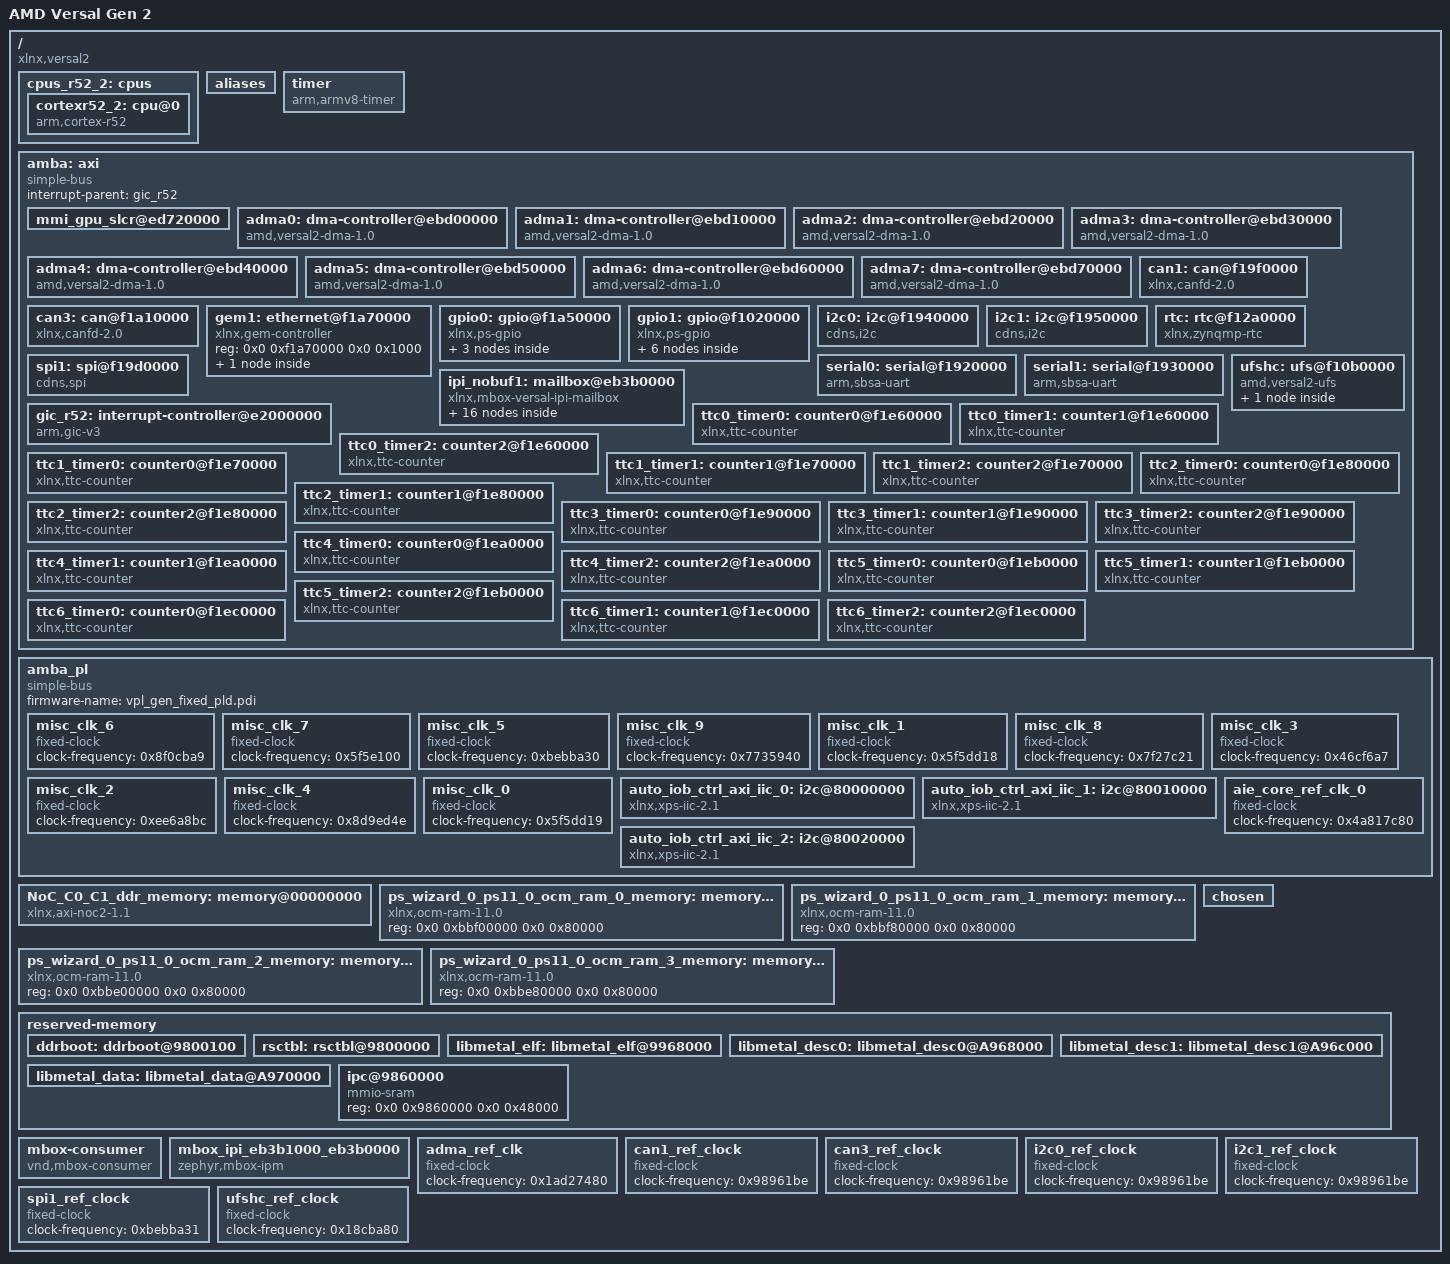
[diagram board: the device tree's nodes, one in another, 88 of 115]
/dts-v1/;
/ {
        compatible = "xlnx,versal2";
        model = "AMD Versal Gen 2";
        #address-cells = <0x2>;
        #size-cells = <0x2>;
        interrupt-parent = <&gic_r52>;
        device_id = "xc2ve3558";
        xlnx,ddrmc5-debug-elf = "false";
        xlnx,ddrmc5-i2c-master = "PMC";
        slrcount = <0x1>;
        family = "Versal_2VE_2VM";
        speed_grade = "2MP";
        pruned-sdt = <0x1>;

        cpus_r52_2: cpus {
                phandle = <0x192>;
                #address-cells = <0x1>;
                #size-cells = <0x0>;

                cortexr52_2: cpu@0 {
                        phandle = <0x193>;
                        compatible = "arm,cortex-r52";
                        device_type = "cpu";
                        reg = <0x2>;
                        clock-frequency = <0x5f5dd19>;
                };
        };

        aliases {
                serial0 = "/axi/serial@f1920000";
                serial1 = "/axi/serial@f1930000";
                i2c0 = "/axi/i2c@f1940000";
                i2c1 = "/axi/i2c@f1950000";
                i2c2 = "/amba_pl/i2c@80000000";
                i2c3 = "/amba_pl/i2c@80010000";
                i2c4 = "/amba_pl/i2c@80020000";
                spi3 = "/axi/spi@f19d0000";
                ethernet0 = "/axi/ethernet@f1a70000";
                ufs0 = "/axi/ufs@f10b0000";
                rtc = "/axi/rtc@f12a0000";
        };

        timer: timer {
                phandle = <0x1b6>;
                compatible = "arm,armv8-timer";
                interrupts = <0x1 0xd 0x4 0xa4 0x1 0xe 0x4 0xa4 0x1 0xb 0x4 0xa4 0x1 0xa 0x4 0xa4>;
        };

        amba: axi {
                phandle = <0x2>;
                compatible = "simple-bus";
                bootph-all;
                #address-cells = <0x2>;
                #size-cells = <0x2>;
                ranges;
                interrupt-parent = <&gic_r52>;

                mmi_gpu_slcr@ed720000 {
                        reg = <0x0 0xed720000 0x0 0x20000>;
                        no-map;
                };

                adma0: dma-controller@ebd00000 {
                        phandle = <0x71>;
                        compatible = "amd,versal2-dma-1.0";
                        reg = <0x0 0xebd00000 0x0 0x1000>;
                        interrupts = <0x0 0x48 0x4 0xa0>;
                        clock-names = "clk_main", "clk_apb";
                        #dma-cells = <0x1>;
                        xlnx,bus-width = <0x40>;
                        clocks = <&adma_ref_clk>, <&adma_ref_clk>;
                };

                adma1: dma-controller@ebd10000 {
                        phandle = <0x72>;
                        compatible = "amd,versal2-dma-1.0";
                        reg = <0x0 0xebd10000 0x0 0x1000>;
                        interrupts = <0x0 0x49 0x4 0xa0>;
                        clock-names = "clk_main", "clk_apb";
                        #dma-cells = <0x1>;
                        xlnx,bus-width = <0x40>;
                        clocks = <&adma_ref_clk>, <&adma_ref_clk>;
                };

                adma2: dma-controller@ebd20000 {
                        phandle = <0x73>;
                        compatible = "amd,versal2-dma-1.0";
                        reg = <0x0 0xebd20000 0x0 0x1000>;
                        interrupts = <0x0 0x4a 0x4 0xa0>;
                        clock-names = "clk_main", "clk_apb";
                        #dma-cells = <0x1>;
                        xlnx,bus-width = <0x40>;
                        clocks = <&adma_ref_clk>, <&adma_ref_clk>;
                };

                adma3: dma-controller@ebd30000 {
                        phandle = <0x74>;
                        compatible = "amd,versal2-dma-1.0";
                        reg = <0x0 0xebd30000 0x0 0x1000>;
                        interrupts = <0x0 0x4b 0x4 0xa0>;
                        clock-names = "clk_main", "clk_apb";
                        #dma-cells = <0x1>;
                        xlnx,bus-width = <0x40>;
                        clocks = <&adma_ref_clk>, <&adma_ref_clk>;
                };

                adma4: dma-controller@ebd40000 {
                        phandle = <0x75>;
                        compatible = "amd,versal2-dma-1.0";
                        reg = <0x0 0xebd40000 0x0 0x1000>;
                        interrupts = <0x0 0x4c 0x4 0xa0>;
                        clock-names = "clk_main", "clk_apb";
                        #dma-cells = <0x1>;
                        xlnx,bus-width = <0x40>;
                        clocks = <&adma_ref_clk>, <&adma_ref_clk>;
                };

                adma5: dma-controller@ebd50000 {
                        phandle = <0x76>;
                        compatible = "amd,versal2-dma-1.0";
                        reg = <0x0 0xebd50000 0x0 0x1000>;
                        interrupts = <0x0 0x4d 0x4 0xa0>;
                        clock-names = "clk_main", "clk_apb";
                        #dma-cells = <0x1>;
                        xlnx,bus-width = <0x40>;
                        clocks = <&adma_ref_clk>, <&adma_ref_clk>;
                };

                adma6: dma-controller@ebd60000 {
                        phandle = <0x77>;
                        compatible = "amd,versal2-dma-1.0";
                        reg = <0x0 0xebd60000 0x0 0x1000>;
                        interrupts = <0x0 0x4e 0x4 0xa0>;
                        clock-names = "clk_main", "clk_apb";
                        #dma-cells = <0x1>;
                        xlnx,bus-width = <0x40>;
                        clocks = <&adma_ref_clk>, <&adma_ref_clk>;
                };

                adma7: dma-controller@ebd70000 {
                        phandle = <0x78>;
                        compatible = "amd,versal2-dma-1.0";
                        reg = <0x0 0xebd70000 0x0 0x1000>;
                        interrupts = <0x0 0x4f 0x4 0xa0>;
                        clock-names = "clk_main", "clk_apb";
                        #dma-cells = <0x1>;
                        xlnx,bus-width = <0x40>;
                        clocks = <&adma_ref_clk>, <&adma_ref_clk>;
                };

                can1: can@f19f0000 {
                        phandle = <0xbd>;
                        compatible = "xlnx,canfd-2.0";
                        reg = <0x0 0xf19f0000 0x0 0x6000>;
                        interrupts = <0x0 0x1c 0x4 0xa0>;
                        clocks = <&can1_ref_clock>;
                };

                can3: can@f1a10000 {
                        phandle = <0xbe>;
                        compatible = "xlnx,canfd-2.0";
                        reg = <0x0 0xf1a10000 0x0 0x6000>;
                        interrupts = <0x0 0x60 0x4 0xa0>;
                        clocks = <&can3_ref_clock>;
                };

                gem1: ethernet@f1a70000 {
                        phandle = <0xc2>;
                        compatible = "xlnx,gem-controller";
                        status = "okay";
                        reg = <0x0 0xf1a70000 0x0 0x1000>;

                        gem1_mac: ethernet_mac {
                                compatible = "xlnx,gem";
                                status = "okay";
                                clock-frequency = <0x7735464>;
                                interrupts = <0x0 0x29 0x4 0xa0 0x0 0x29 0x4 0xa0>;
                                amba-ahb-burst-length = <0x10>;
                                hw-rx-buffer-size = <0x3>;
                                hw-rx-buffer-offset = <0x0>;
                                hw-tx-buffer-size-full;
                                rx-buffer-descriptors = <0x20>;
                                tx-buffer-descriptors = <0x20>;
                                rx-buffer-size = <0x600>;
                                tx-buffer-size = <0x600>;
                                discard-rx-fcs;
                                unicast-hash;
                                local-mac-address = [00 0A 35 00 01 02];
                        };
                };

                gpio0: gpio@f1a50000 {
                        phandle = <0xc1>;
                        compatible = "xlnx,ps-gpio";
                        reg = <0x0 0xf1a50000 0x0 0x1000>;
                        interrupts = <0x0 0x14 0x4 0xa0>;
                        #address-cells = <0x1>;
                        #size-cells = <0x0>;

                        gpio0_bank0: gpio0_bank@0 {
                                compatible = "xlnx,ps-gpio-bank";
                                reg = <0x0>;
                                #gpio-cells = <0x2>;
                                gpio-controller;
                                ngpios = <0x1a>;
                        };

                        gpio0_bank3: gpio0_bank@3 {
                                compatible = "xlnx,ps-gpio-bank";
                                reg = <0x3>;
                                #gpio-cells = <0x2>;
                                gpio-controller;
                                ngpios = <0x20>;
                        };

                        gpio0_bank4: gpio0_bank@4 {
                                compatible = "xlnx,ps-gpio-bank";
                                reg = <0x4>;
                                #gpio-cells = <0x2>;
                                gpio-controller;
                                ngpios = <0x20>;
                        };
                };

                gpio1: gpio@f1020000 {
                        phandle = <0xa0>;
                        compatible = "xlnx,ps-gpio";
                        reg = <0x0 0xf1020000 0x0 0x1000>;
                        interrupts = <0x0 0xca 0x4 0xa0>;
                        #address-cells = <0x1>;
                        #size-cells = <0x0>;

                        gpio1_bank0: gpio1_bank@0 {
                                compatible = "xlnx,ps-gpio-bank";
                                reg = <0x0>;
                                #gpio-cells = <0x2>;
                                gpio-controller;
                                ngpios = <0x1a>;
                        };

                        gpio1_bank1: gpio1_bank@1 {
                                compatible = "xlnx,ps-gpio-bank";
                                reg = <0x1>;
                                #gpio-cells = <0x2>;
                                gpio-controller;
                                ngpios = <0x1a>;
                        };

                        gpio1_bank3: gpio1_bank@3 {
                                compatible = "xlnx,ps-gpio-bank";
                                reg = <0x3>;
                                #gpio-cells = <0x2>;
                                gpio-controller;
                                ngpios = <0x20>;
                        };

                        gpio1_bank4: gpio1_bank@4 {
                                compatible = "xlnx,ps-gpio-bank";
                                reg = <0x4>;
                                #gpio-cells = <0x2>;
                                gpio-controller;
                                ngpios = <0x20>;
                        };

                        gpio1_bank2: gpio1_bank@2 {
                                compatible = "xlnx,ps-gpio-bank";
                                reg = <0x2>;
                                #gpio-cells = <0x2>;
                                gpio-controller;
                                ngpios = <0x1a>;
                        };

                        gpio1_bank5: gpio1_bank@5 {
                                compatible = "xlnx,ps-gpio-bank";
                                reg = <0x5>;
                                #gpio-cells = <0x2>;
                                gpio-controller;
                                ngpios = <0x20>;
                        };
                };

                i2c0: i2c@f1940000 {
                        phandle = <0xba>;
                        compatible = "cdns,i2c";
                        status = "okay";
                        reg = <0x0 0xf1940000 0x0 0x1000>;
                        interrupt-parent = <&gic_r52>;
                        interrupts = <0x0 0x15 0x4 0xa0>;
                        clock-frequency = <0x186a0>;
                        fifo-depth = <0x10>;
                        #address-cells = <0x1>;
                        #size-cells = <0x0>;
                        clocks = <&i2c0_ref_clock>;
                };

                i2c1: i2c@f1950000 {
                        phandle = <0xbb>;
                        compatible = "cdns,i2c";
                        status = "okay";
                        reg = <0x0 0xf1950000 0x0 0x1000>;
                        interrupt-parent = <&gic_r52>;
                        interrupts = <0x0 0x16 0x4 0xa0>;
                        clock-frequency = <0x186a0>;
                        fifo-depth = <0x10>;
                        #address-cells = <0x1>;
                        #size-cells = <0x0>;
                        clocks = <&i2c1_ref_clock>;
                };

                rtc: rtc@f12a0000 {
                        phandle = <0xb1>;
                        compatible = "xlnx,zynqmp-rtc";
                        status = "okay";
                        reg = <0x0 0xf12a0000 0x0 0x100>;
                        interrupt-parent = <&gic_r52>;
                        interrupts = <0x0 0xc8 0x4 0xa0 0x0 0xc9 0x4 0xa0>;
                        interrupt-names = "alarm", "sec";
                        clock-frequency = <0x7fff>;
                };

                serial0: serial@f1920000 {
                        phandle = <0xb8>;
                        compatible = "arm,sbsa-uart";
                        status = "okay";
                        reg = <0x0 0xf1920000 0x0 0x1000>;
                        interrupt-parent = <&gic_r52>;
                        interrupts = <0x0 0x19 0x4 0xa0>;
                        interrupt-names = "serial0";
                };

                serial1: serial@f1930000 {
                        phandle = <0xb9>;
                        compatible = "arm,sbsa-uart";
                        status = "okay";
                        reg = <0x0 0xf1930000 0x0 0x1000>;
                        interrupt-parent = <&gic_r52>;
                        interrupts = <0x0 0x1a 0x4 0xa0>;
                        interrupt-names = "serial1";
                };

                spi1: spi@f19d0000 {
                        phandle = <0xbc>;
                        compatible = "cdns,spi";
                        status = "okay";
                        interrupt-parent = <&gic_r52>;
                        interrupts = <0x0 0x18 0x4 0xa0>;
                        reg = <0x0 0xf19d0000 0x0 0x1000>;
                        #address-cells = <0x1>;
                        #size-cells = <0x0>;
                        clock-frequency = <0xbebba31>;
                        tx-fifo-depth = <0x80>;
                        rx-fifo-depth = <0x80>;
                        fifo-width = <0x8>;
                        clocks = <&spi1_ref_clock>;
                };

                ufshc: ufs@f10b0000 {
                        phandle = <0xa2>;
                        compatible = "amd,versal2-ufs";
                        status = "okay";
                        interrupt-parent = <&gic_r52>;
                        interrupts = <0x0 0xea 0x4 0xa0>;
                        reg = <0x0 0xf10b0000 0x0 0x100 0x0 0xf1060000 0x0 0x2000 0x0 0xf1250000 0x0 0x10000 0x0 0xf1260000 0x0 0x10000>;
                        clock-names = "core", "ref_clk";
                        clocks = <&ufshc_ref_clock>, <&ufshc_ref_clock>;

                        ufsdisk0 {
                                compatible = "zephyr,ufs-disk";
                                disk-name = "UFS";
                        };
                };

                ipi_nobuf1: mailbox@eb3b0000 {
                        phandle = <0xfa>;
                        compatible = "xlnx,mbox-versal-ipi-mailbox";
                        interrupt-parent = <&gic_r52>;
                        interrupts = <0x0 0x40 0x4 0xa0>;
                        reg = <0x0 0xeb3b0000 0x0 0x1000>;
                        xlnx,ipi-id = <0xa>;
                        #address-cells = <0x2>;
                        #size-cells = <0x2>;
                        reg-names = "ctrl";

                        ipi_1_nobuf_to_ipi_asu: child@eb310000 {
                                phandle = <0x257>;
                                compatible = "xlnx,mbox-versal-ipi-dest-mailbox";
                                #mbox-cells = <0x1>;
                                xlnx,ipi-id = <0x0>;
                                reg = <0x0 0xeb310000 0x0 0x10000 0x0 0xeb3f0000 0x0 0x200>;
                                reg-names = "ctrl", "msg";
                        };

                        ipi_1_nobuf_to_ipi_0: child@eb330000 {
                                phandle = <0x258>;
                                compatible = "xlnx,mbox-versal-ipi-dest-mailbox";
                                #mbox-cells = <0x1>;
                                xlnx,ipi-id = <0x2>;
                                reg = <0x0 0xeb330000 0x0 0x10000 0x0 0xeb3f0400 0x0 0x200>;
                                reg-names = "ctrl", "msg";
                        };

                        ipi_1_nobuf_to_ipi_1: child@eb340000 {
                                phandle = <0x259>;
                                compatible = "xlnx,mbox-versal-ipi-dest-mailbox";
                                #mbox-cells = <0x1>;
                                xlnx,ipi-id = <0x3>;
                                reg = <0x0 0xeb340000 0x0 0x10000 0x0 0xeb3f0600 0x0 0x200>;
                                reg-names = "ctrl", "msg";
                        };

                        ipi_1_nobuf_to_ipi_1_nobuf: child@eb3b0000 {
                                phandle = <0x25a>;
                                compatible = "xlnx,mbox-versal-ipi-dest-mailbox";
                                #mbox-cells = <0x1>;
                                xlnx,ipi-id = <0xa>;
                                reg = <0x0 0xeb3b0000 0x0 0x1000>;
                                reg-names = "ctrl";
                        };

                        ipi_1_nobuf_to_ipi_2: child@eb350000 {
                                phandle = <0x25b>;
                                compatible = "xlnx,mbox-versal-ipi-dest-mailbox";
                                #mbox-cells = <0x1>;
                                xlnx,ipi-id = <0x4>;
                                reg = <0x0 0xeb350000 0x0 0x10000 0x0 0xeb3f0800 0x0 0x200>;
                                reg-names = "ctrl", "msg";
                        };

                        ipi_1_nobuf_to_ipi_2_nobuf: child@eb3b1000 {
                                phandle = <0x25c>;
                                compatible = "xlnx,mbox-versal-ipi-dest-mailbox";
                                #mbox-cells = <0x1>;
                                xlnx,ipi-id = <0xb>;
                                reg = <0x0 0xeb3b1000 0x0 0x1000>;
                                reg-names = "ctrl";
                        };

                        ipi_1_nobuf_to_ipi_3: child@eb360000 {
                                phandle = <0x25d>;
                                compatible = "xlnx,mbox-versal-ipi-dest-mailbox";
                                #mbox-cells = <0x1>;
                                xlnx,ipi-id = <0x5>;
                                reg = <0x0 0xeb360000 0x0 0x10000 0x0 0xeb3f0a00 0x0 0x200>;
                                reg-names = "ctrl", "msg";
                        };

                        ipi_1_nobuf_to_ipi_3_nobuf: child@eb3b2000 {
                                phandle = <0x25e>;
                                compatible = "xlnx,mbox-versal-ipi-dest-mailbox";
                                #mbox-cells = <0x1>;
                                xlnx,ipi-id = <0xc>;
                                reg = <0x0 0xeb3b2000 0x0 0x1000>;
                                reg-names = "ctrl";
                        };

                        ipi_1_nobuf_to_ipi_4: child@eb370000 {
                                phandle = <0x25f>;
                                compatible = "xlnx,mbox-versal-ipi-dest-mailbox";
                                #mbox-cells = <0x1>;
                                xlnx,ipi-id = <0x6>;
                                reg = <0x0 0xeb370000 0x0 0x10000 0x0 0xeb3f0c00 0x0 0x200>;
                                reg-names = "ctrl", "msg";
                        };

                        ipi_1_nobuf_to_ipi_4_nobuf: child@eb3b3000 {
                                phandle = <0x260>;
                                compatible = "xlnx,mbox-versal-ipi-dest-mailbox";
                                #mbox-cells = <0x1>;
                                xlnx,ipi-id = <0xd>;
                                reg = <0x0 0xeb3b3000 0x0 0x1000>;
                                reg-names = "ctrl";
                        };

                        ipi_1_nobuf_to_ipi_5: child@eb380000 {
                                phandle = <0x261>;
                                compatible = "xlnx,mbox-versal-ipi-dest-mailbox";
                                #mbox-cells = <0x1>;
                                xlnx,ipi-id = <0x7>;
                                reg = <0x0 0xeb380000 0x0 0x10000 0x0 0xeb3f0e00 0x0 0x200>;
                                reg-names = "ctrl", "msg";
                        };

                        ipi_1_nobuf_to_ipi_5_nobuf: child@eb3b4000 {
                                phandle = <0x262>;
                                compatible = "xlnx,mbox-versal-ipi-dest-mailbox";
                                #mbox-cells = <0x1>;
                                xlnx,ipi-id = <0xe>;
                                reg = <0x0 0xeb3b4000 0x0 0x1000>;
                                reg-names = "ctrl";
                        };

                        ipi_1_nobuf_to_ipi_6: child@eb3a0000 {
                                phandle = <0x263>;
                                compatible = "xlnx,mbox-versal-ipi-dest-mailbox";
                                #mbox-cells = <0x1>;
                                xlnx,ipi-id = <0x9>;
                                reg = <0x0 0xeb3a0000 0x0 0x10000>;
                                reg-names = "ctrl";
                        };

                        ipi_1_nobuf_to_ipi_6_nobuf: child@eb3b5000 {
                                phandle = <0x264>;
                                compatible = "xlnx,mbox-versal-ipi-dest-mailbox";
                                #mbox-cells = <0x1>;
                                xlnx,ipi-id = <0xf>;
                                reg = <0x0 0xeb3b5000 0x0 0x1000>;
                                reg-names = "ctrl";
                        };

                        ipi_1_nobuf_to_ipi_pmc: child@eb320000 {
                                phandle = <0x265>;
                                compatible = "xlnx,mbox-versal-ipi-dest-mailbox";
                                #mbox-cells = <0x1>;
                                xlnx,ipi-id = <0x1>;
                                reg = <0x0 0xeb320000 0x0 0x10000 0x0 0xeb3f0200 0x0 0x200>;
                                reg-names = "ctrl", "msg";
                        };

                        ipi_1_nobuf_to_ipi_pmc_nobuf: child@eb390000 {
                                phandle = <0x266>;
                                compatible = "xlnx,mbox-versal-ipi-dest-mailbox";
                                #mbox-cells = <0x1>;
                                xlnx,ipi-id = <0x8>;
                                reg = <0x0 0xeb390000 0x0 0x10000>;
                                reg-names = "ctrl";
                        };
                };

                gic_r52: interrupt-controller@e2000000  {
                        phandle = <0xf6>;
                        status = "okay";
                        reg = <0x0 0xe2000000 0x0 0x10000 0x0 0xe2100000 0x0 0x80000>;
                        interrupt-controller;
                        #interrupt-cells = <0x4>;
                        compatible = "arm,gic-v3", "arm,gic";
                };

                ttc0_timer0: counter0@f1e60000 {
                        compatible = "xlnx,ttc-counter";
                        clock-frequency = <0x8f0cba9>;
                        reg = <0x0 0xf1e60000 0x0 0x1000>;
                        interrupt-parent = <&gic_r52>;
                        timer-id = <0x0>;
                        interrupts = <0x0 0x2b 0x4 0xa0>;
                        timer-width = <0x20>;
                };

                ttc0_timer1: counter1@f1e60000 {
                        compatible = "xlnx,ttc-counter";
                        clock-frequency = <0x8f0cba9>;
                        reg = <0x0 0xf1e60000 0x0 0x1000>;
                        interrupt-parent = <&gic_r52>;
                        timer-id = <0x1>;
                        interrupts = <0x0 0x2b 0x4 0xa0>;
                        timer-width = <0x20>;
                };

                ttc0_timer2: counter2@f1e60000 {
                        compatible = "xlnx,ttc-counter";
                        clock-frequency = <0x8f0cba9>;
                        reg = <0x0 0xf1e60000 0x0 0x1000>;
                        interrupt-parent = <&gic_r52>;
                        timer-id = <0x2>;
                        interrupts = <0x0 0x2b 0x4 0xa0>;
                        timer-width = <0x20>;
                };

                ttc1_timer0: counter0@f1e70000 {
                        compatible = "xlnx,ttc-counter";
                        clock-frequency = <0x8f0cba9>;
                        reg = <0x0 0xf1e70000 0x0 0x1000>;
                        interrupt-parent = <&gic_r52>;
                        timer-id = <0x0>;
                        interrupts = <0x0 0x2c 0x4 0xa0>;
                        timer-width = <0x20>;
                };

                ttc1_timer1: counter1@f1e70000 {
                        compatible = "xlnx,ttc-counter";
                        clock-frequency = <0x8f0cba9>;
                        reg = <0x0 0xf1e70000 0x0 0x1000>;
                        interrupt-parent = <&gic_r52>;
                        timer-id = <0x1>;
                        interrupts = <0x0 0x2c 0x4 0xa0>;
                        timer-width = <0x20>;
                };

                ttc1_timer2: counter2@f1e70000 {
                        compatible = "xlnx,ttc-counter";
                        clock-frequency = <0x8f0cba9>;
                        reg = <0x0 0xf1e70000 0x0 0x1000>;
                        interrupt-parent = <&gic_r52>;
                        timer-id = <0x2>;
                        interrupts = <0x0 0x2c 0x4 0xa0>;
                        timer-width = <0x20>;
                };

                ttc2_timer0: counter0@f1e80000 {
                        compatible = "xlnx,ttc-counter";
                        clock-frequency = <0x8f0cba9>;
                        reg = <0x0 0xf1e80000 0x0 0x1000>;
                        interrupt-parent = <&gic_r52>;
                        timer-id = <0x0>;
                        interrupts = <0x0 0x2d 0x4 0xa0>;
                        timer-width = <0x20>;
                };

                ttc2_timer1: counter1@f1e80000 {
                        compatible = "xlnx,ttc-counter";
                        clock-frequency = <0x8f0cba9>;
                        reg = <0x0 0xf1e80000 0x0 0x1000>;
                        interrupt-parent = <&gic_r52>;
                        timer-id = <0x1>;
                        interrupts = <0x0 0x2d 0x4 0xa0>;
                        timer-width = <0x20>;
                };

                ttc2_timer2: counter2@f1e80000 {
                        compatible = "xlnx,ttc-counter";
                        clock-frequency = <0x8f0cba9>;
                        reg = <0x0 0xf1e80000 0x0 0x1000>;
                        interrupt-parent = <&gic_r52>;
                        timer-id = <0x2>;
                        interrupts = <0x0 0x2d 0x4 0xa0>;
                        timer-width = <0x20>;
                };

                ttc3_timer0: counter0@f1e90000 {
                        compatible = "xlnx,ttc-counter";
                        clock-frequency = <0x8f0cba9>;
                        reg = <0x0 0xf1e90000 0x0 0x1000>;
                        interrupt-parent = <&gic_r52>;
                        timer-id = <0x0>;
                        interrupts = <0x0 0x2e 0x4 0xa0>;
                        timer-width = <0x20>;
                };

                ttc3_timer1: counter1@f1e90000 {
                        compatible = "xlnx,ttc-counter";
                        clock-frequency = <0x8f0cba9>;
                        reg = <0x0 0xf1e90000 0x0 0x1000>;
                        interrupt-parent = <&gic_r52>;
                        timer-id = <0x1>;
                        interrupts = <0x0 0x2e 0x4 0xa0>;
                        timer-width = <0x20>;
                };

                ttc3_timer2: counter2@f1e90000 {
                        compatible = "xlnx,ttc-counter";
                        clock-frequency = <0x8f0cba9>;
                        reg = <0x0 0xf1e90000 0x0 0x1000>;
                        interrupt-parent = <&gic_r52>;
                        timer-id = <0x2>;
                        interrupts = <0x0 0x2e 0x4 0xa0>;
                        timer-width = <0x20>;
                };

                ttc4_timer0: counter0@f1ea0000 {
                        compatible = "xlnx,ttc-counter";
                        clock-frequency = <0x8f0cba9>;
                        reg = <0x0 0xf1ea0000 0x0 0x1000>;
                        interrupt-parent = <&gic_r52>;
                        timer-id = <0x0>;
                        interrupts = <0x0 0x2f 0x4 0xa0>;
                        timer-width = <0x20>;
                };

                ttc4_timer1: counter1@f1ea0000 {
                        compatible = "xlnx,ttc-counter";
                        clock-frequency = <0x8f0cba9>;
                        reg = <0x0 0xf1ea0000 0x0 0x1000>;
                        interrupt-parent = <&gic_r52>;
                        timer-id = <0x1>;
                        interrupts = <0x0 0x2f 0x4 0xa0>;
                        timer-width = <0x20>;
                };

                ttc4_timer2: counter2@f1ea0000 {
                        compatible = "xlnx,ttc-counter";
                        clock-frequency = <0x8f0cba9>;
                        reg = <0x0 0xf1ea0000 0x0 0x1000>;
                        interrupt-parent = <&gic_r52>;
                        timer-id = <0x2>;
                        interrupts = <0x0 0x2f 0x4 0xa0>;
                        timer-width = <0x20>;
                };

                ttc5_timer0: counter0@f1eb0000 {
                        compatible = "xlnx,ttc-counter";
                        clock-frequency = <0x8f0cba9>;
                        reg = <0x0 0xf1eb0000 0x0 0x1000>;
                        interrupt-parent = <&gic_r52>;
                        timer-id = <0x0>;
                        interrupts = <0x0 0x30 0x4 0xa0>;
                        timer-width = <0x20>;
                };

                ttc5_timer1: counter1@f1eb0000 {
                        compatible = "xlnx,ttc-counter";
                        clock-frequency = <0x8f0cba9>;
                        reg = <0x0 0xf1eb0000 0x0 0x1000>;
                        interrupt-parent = <&gic_r52>;
                        timer-id = <0x1>;
                        interrupts = <0x0 0x30 0x4 0xa0>;
                        timer-width = <0x20>;
                };

                ttc5_timer2: counter2@f1eb0000 {
                        compatible = "xlnx,ttc-counter";
                        clock-frequency = <0x8f0cba9>;
                        reg = <0x0 0xf1eb0000 0x0 0x1000>;
                        interrupt-parent = <&gic_r52>;
                        timer-id = <0x2>;
                        interrupts = <0x0 0x30 0x4 0xa0>;
                        timer-width = <0x20>;
                };

                ttc6_timer0: counter0@f1ec0000 {
                        compatible = "xlnx,ttc-counter";
                        clock-frequency = <0x8f0cba9>;
                        reg = <0x0 0xf1ec0000 0x0 0x1000>;
                        interrupt-parent = <&gic_r52>;
                        timer-id = <0x0>;
                        interrupts = <0x0 0x31 0x4 0xa0>;
                        timer-width = <0x20>;
                };

                ttc6_timer1: counter1@f1ec0000 {
                        compatible = "xlnx,ttc-counter";
                        clock-frequency = <0x8f0cba9>;
                        reg = <0x0 0xf1ec0000 0x0 0x1000>;
                        interrupt-parent = <&gic_r52>;
                        timer-id = <0x1>;
                        interrupts = <0x0 0x31 0x4 0xa0>;
                        timer-width = <0x20>;
                };

                ttc6_timer2: counter2@f1ec0000 {
                        compatible = "xlnx,ttc-counter";
                        clock-frequency = <0x8f0cba9>;
                        reg = <0x0 0xf1ec0000 0x0 0x1000>;
                        interrupt-parent = <&gic_r52>;
                        timer-id = <0x2>;
                        interrupts = <0x0 0x31 0x4 0xa0>;
                        timer-width = <0x20>;
                };
        };

        amba_pl: amba_pl {
                phandle = <0x2ef>;
                ranges;
                compatible = "simple-bus";
                #address-cells = <0x2>;
                #size-cells = <0x2>;
                firmware-name = "vpl_gen_fixed_pld.pdi";

                misc_clk_6: misc_clk_6 {
                        phandle = <0x140>;
                        compatible = "fixed-clock";
                        clock-frequency = <0x8f0cba9>;
                        #clock-cells = <0x0>;
                };

                misc_clk_7: misc_clk_7 {
                        phandle = <0x142>;
                        compatible = "fixed-clock";
                        clock-frequency = <0x5f5e100>;
                        #clock-cells = <0x0>;
                };

                misc_clk_5: misc_clk_5 {
                        phandle = <0x13f>;
                        compatible = "fixed-clock";
                        clock-frequency = <0xbebba30>;
                        #clock-cells = <0x0>;
                };

                misc_clk_9: misc_clk_9 {
                        phandle = <0x146>;
                        compatible = "fixed-clock";
                        clock-frequency = <0x7735940>;
                        #clock-cells = <0x0>;
                };

                misc_clk_1: misc_clk_1 {
                        phandle = <0x13a>;
                        compatible = "fixed-clock";
                        clock-frequency = <0x5f5dd18>;
                        #clock-cells = <0x0>;
                };

                misc_clk_8: misc_clk_8 {
                        phandle = <0x145>;
                        compatible = "fixed-clock";
                        clock-frequency = <0x7f27c21>;
                        #clock-cells = <0x0>;
                };

                misc_clk_3: misc_clk_3 {
                        phandle = <0x13d>;
                        compatible = "fixed-clock";
                        clock-frequency = <0x46cf6a7>;
                        #clock-cells = <0x0>;
                };

                misc_clk_2: misc_clk_2 {
                        phandle = <0x13c>;
                        compatible = "fixed-clock";
                        clock-frequency = <0xee6a8bc>;
                        #clock-cells = <0x0>;
                };

                misc_clk_4: misc_clk_4 {
                        phandle = <0x13e>;
                        compatible = "fixed-clock";
                        clock-frequency = <0x8d9ed4e>;
                        #clock-cells = <0x0>;
                };

                misc_clk_0: misc_clk_0 {
                        phandle = <0x139>;
                        compatible = "fixed-clock";
                        clock-frequency = <0x5f5dd19>;
                        #clock-cells = <0x0>;
                };

                auto_iob_ctrl_axi_iic_0: i2c@80000000 {
                        phandle = <0xf2>;
                        interrupts = <0x0 0x5a 0x4 0xa0>;
                        compatible = "xlnx,xps-iic-2.1";
                        interrupt-parent = <&gic_r52>;
                        reg = <0x0 0x80000000 0x0 0x10000>;
                        #address-cells = <0x1>;
                        #size-cells = <0x0>;
                };

                auto_iob_ctrl_axi_iic_1: i2c@80010000 {
                        phandle = <0xf3>;
                        interrupts = <0x0 0x58 0x4 0xa0>;
                        compatible = "xlnx,xps-iic-2.1";
                        interrupt-parent = <&gic_r52>;
                        reg = <0x0 0x80010000 0x0 0x10000>;
                        #address-cells = <0x1>;
                        #size-cells = <0x0>;
                };

                auto_iob_ctrl_axi_iic_2: i2c@80020000 {
                        phandle = <0xf4>;
                        interrupts = <0x0 0x59 0x4 0xa0>;
                        compatible = "xlnx,xps-iic-2.1";
                        interrupt-parent = <&gic_r52>;
                        reg = <0x0 0x80020000 0x0 0x10000>;
                        #address-cells = <0x1>;
                        #size-cells = <0x0>;
                };

                aie_core_ref_clk_0: aie_core_ref_clk_0 {
                        phandle = <0x13b>;
                        compatible = "fixed-clock";
                        clock-frequency = <0x4a817c80>;
                        #clock-cells = <0x0>;
                };
        };

        NoC_C0_C1_ddr_memory: memory@00000000 {
                phandle = <0x4>;
                compatible = "xlnx,axi-noc2-1.1";
                xlnx,ip-name = "axi_noc2";
                device_type = "memory";
                reg = <0x0 0x100000 0x0 0x7ff00000>;
                memory_type = "memory";
        };

        ps_wizard_0_ps11_0_ocm_ram_0_memory: memory@BBF00000 {
                phandle = <0x19>;
                compatible = "xlnx,ocm-ram-11.0", "mmio-sram";
                device_type = "memory";
                reg = <0x0 0xbbf00000 0x0 0x80000>;
        };

        ps_wizard_0_ps11_0_ocm_ram_1_memory: memory@BBF80000 {
                phandle = <0x1a>;
                compatible = "xlnx,ocm-ram-11.0", "mmio-sram";
                device_type = "memory";
                reg = <0x0 0xbbf80000 0x0 0x80000>;
        };

        ps_wizard_0_ps11_0_ocm_ram_2_memory: memory@BBE00000 {
                phandle = <0x1b>;
                compatible = "xlnx,ocm-ram-11.0", "mmio-sram";
                device_type = "memory";
                reg = <0x0 0xbbe00000 0x0 0x80000>;
        };

        ps_wizard_0_ps11_0_ocm_ram_3_memory: memory@BBE80000 {
                phandle = <0x1c>;
                compatible = "xlnx,ocm-ram-11.0", "mmio-sram";
                device_type = "memory";
                reg = <0x0 0xbbe80000 0x0 0x80000>;
        };

        chosen {
                stdout-path = "serial1:115200n8";
                bootargs = "earlycon=pl011,mmio32,0xf1930000 console=ttyAMA1,115200";
                zephyr,console = "serial1";
                zephyr,shell-uart = "serial1";
                zephyr,ipc_shm = "/reserved-memory/ipc@9860000";
                zephyr,ipc = "/mbox_ipi_eb3b1000_eb3b0000";
                zephyr,sram = "/reserved-memory/ddrboot@9800100";
        };

        reserved-memory {
                #size-cells = <0x2>;
                #address-cells = <0x2>;
                ranges;

                ddrboot: ddrboot@9800100 {
                        phandle = <0x36f>;
                        label = "ddrboot";
                        no-map;
                        reg = <0x0 0x9800100 0x0 0x5ff00>;
                        device_type = "memory";
                };

                rsctbl: rsctbl@9800000 {
                        phandle = <0x370>;
                        label = "rsctbl";
                        no-map;
                        reg = <0x0 0x9800000 0x0 0x100>;
                };

                libmetal_elf: libmetal_elf@9968000 {
                        phandle = <0x377>;
                        label = "libmetal_elf";
                        no-map;
                        reg = <0x0 0x9968000 0x0 0x1000000>;
                };

                libmetal_desc0: libmetal_desc0@A968000 {
                        phandle = <0x378>;
                        label = "libmetal_desc0";
                        no-map;
                        reg = <0x0 0xa968000 0x0 0x4000>;
                };

                libmetal_desc1: libmetal_desc1@A96c000 {
                        phandle = <0x379>;
                        label = "libmetal_desc1";
                        no-map;
                        reg = <0x0 0xa96c000 0x0 0x4000>;
                };

                libmetal_data: libmetal_data@A970000 {
                        phandle = <0x37a>;
                        label = "libmetal_data";
                        no-map;
                        reg = <0x0 0xa970000 0x0 0x40000>;
                };

                ipc@9860000 {
                        reg = <0x0 0x9860000 0x0 0x48000>;
                        compatible = "mmio-sram";
                };
        };

        mbox-consumer {
                compatible = "vnd,mbox-consumer";
                mboxes = <&ipi_1_nobuf_to_ipi_2_nobuf 0x0>,
                 <&ipi_1_nobuf_to_ipi_2_nobuf 0x1>;
                mbox-names = "tx", "rx";
        };

        mbox_ipi_eb3b1000_eb3b0000 {
                compatible = "zephyr,mbox-ipm";
                mbox-names = "tx", "rx";
                status = "okay";
                mboxes = <&ipi_1_nobuf_to_ipi_2_nobuf 0x0>,
                 <&ipi_1_nobuf_to_ipi_2_nobuf 0x1>;
        };

        adma_ref_clk: adma_ref_clk {
                compatible = "fixed-clock";
                #clock-cells = <0x0>;
                clock-frequency = <0x1ad27480>;
        };

        can1_ref_clock: can1_ref_clock {
                compatible = "fixed-clock";
                #clock-cells = <0x0>;
                clock-frequency = <0x98961be>;
        };

        can3_ref_clock: can3_ref_clock {
                compatible = "fixed-clock";
                #clock-cells = <0x0>;
                clock-frequency = <0x98961be>;
        };

        i2c0_ref_clock: i2c0_ref_clock {
                compatible = "fixed-clock";
                #clock-cells = <0x0>;
                clock-frequency = <0x98961be>;
        };

        i2c1_ref_clock: i2c1_ref_clock {
                compatible = "fixed-clock";
                #clock-cells = <0x0>;
                clock-frequency = <0x98961be>;
        };

        spi1_ref_clock: spi1_ref_clock {
                compatible = "fixed-clock";
                #clock-cells = <0x0>;
                clock-frequency = <0xbebba31>;
        };

        ufshc_ref_clock: ufshc_ref_clock {
                compatible = "fixed-clock";
                #clock-cells = <0x0>;
                clock-frequency = <0x18cba80>;
        };
};
